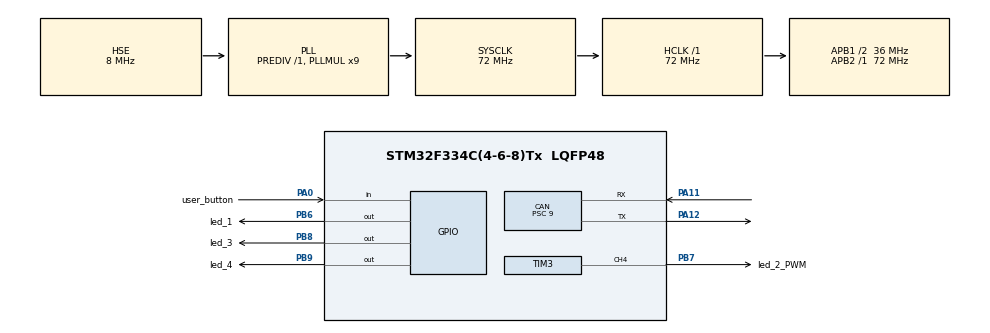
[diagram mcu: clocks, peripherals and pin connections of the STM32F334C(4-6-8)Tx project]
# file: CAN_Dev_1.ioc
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CAN.ABOM=ENABLE
CAN.BS1=CAN_BS1_13TQ
CAN.BS2=CAN_BS2_2TQ
CAN.CalculateBaudRate=250000
CAN.CalculateTimeBit=4000
CAN.CalculateTimeQuantum=250.0
CAN.NART=ENABLE
CAN.Prescaler=9
CAN.TXFP=ENABLE
Mcu.Family=STM32F3
Mcu.Name=STM32F334C(4-6-8)Tx
Mcu.Package=LQFP48
NVIC.CAN_RX0_IRQn=true\:11\:0\:true\:false\:true\:true\:true\:true
NVIC.CAN_TX_IRQn=true\:12\:0\:true\:false\:true\:true\:true\:true
NVIC.PriorityGroup=NVIC_PRIORITYGROUP_4
PA0.GPIO_Label=user_button
PA0.Signal=GPIO_Input
PA11.Mode=CAN_Activate
PA11.Signal=CAN_RX
PA12.Mode=CAN_Activate
PA12.Signal=CAN_TX
PA13.Mode=Serial_Wire
PA13.Signal=SYS_JTMS-SWDIO
PA14.Mode=Serial_Wire
PA14.Signal=SYS_JTCK-SWCLK
PB6.GPIO_Label=led_1
PB6.Signal=GPIO_Output
PB7.GPIO_Label=led_2_PWM
PB7.Signal=S_TIM3_CH4
PB8.GPIO_Label=led_3
PB8.Signal=GPIO_Output
PB9.GPIO_Label=led_4
PB9.Signal=GPIO_Output
PF0\ /\ OSC_IN.Mode=HSE-External-Oscillator
PF0\ /\ OSC_IN.Signal=RCC_OSC_IN
PF1\ /\ OSC_OUT.Mode=HSE-External-Oscillator
PF1\ /\ OSC_OUT.Signal=RCC_OSC_OUT
ProjectManager.HeapSize=0x200
ProjectManager.StackSize=0x400
ProjectManager.TargetToolchain=MDK-ARM V5.32
RCC.AHBFreq_Value=72000000
RCC.APB1CLKDivider=RCC_HCLK_DIV2
RCC.APB1Freq_Value=36000000
RCC.APB1TimFreq_Value=72000000
RCC.APB2Freq_Value=72000000
RCC.APB2TimFreq_Value=72000000
RCC.CortexFreq_Value=72000000
RCC.HCLKFreq_Value=72000000
RCC.HSI_VALUE=8000000
RCC.LSE_VALUE=32768
RCC.PLLMUL=RCC_PLL_MUL9
RCC.PLLSourceVirtual=RCC_PLLSOURCE_HSE
RCC.SYSCLKFreq_VALUE=72000000
RCC.SYSCLKSourceVirtual=RCC_SYSCLKSOURCE_PLLCLK
SH.S_TIM3_CH4.0=TIM3_CH4,PWM Generation4 CH4
TIM3.AutoReloadPreload=TIM_AUTORELOAD_PRELOAD_ENABLE
TIM3.Channel-PWM\ Generation4\ CH4=TIM_CHANNEL_4
TIM3.ClockDivision=TIM_CLOCKDIVISION_DIV4
TIM3.Pulse-PWM\ Generation4\ CH4=32000
board=custom

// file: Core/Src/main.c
/* USER CODE BEGIN Header */
/**
  ******************************************************************************
  * @file           : main.c
  * @brief          : Main program body
  ******************************************************************************
  * @attention
  *
  * Copyright (c) 2023 STMicroelectronics.
  * All rights reserved.
  *
  * This software is licensed under terms that can be found in the LICENSE file
  * in the root directory of this software component.
  * If no LICENSE file comes with this software, it is provided AS-IS.
  *
  ******************************************************************************
  */
/* USER CODE END Header */
#include "main.h"
#include "can.h"
#include "tim.h"
#include "gpio.h"

/* USER CODE BEGIN PV */
uint8_t pulse;
uint8_t pulse2;
uint8_t butSost;

CAN_TxHeaderTypeDef TxHeader;
CAN_RxHeaderTypeDef RxHeader;
uint8_t TxData[8] = {0,};
uint8_t RxData[8] = {0,};
uint32_t TxMailbox = 0;

/* USER CODE END PV */

void SystemClock_Config(void);
/* USER CODE BEGIN PFP */
void ledBlink(uint8_t timeBlink);
/* USER CODE END PFP */

/* USER CODE BEGIN 0 */
void HAL_CAN_RxFifo0MsgPendingCallback(CAN_HandleTypeDef *hcan)
{
    if(HAL_CAN_GetRxMessage(hcan, CAN_RX_FIFO0, &RxHeader, RxData) == HAL_OK)
    {
       pulse2 = RxData[7];
       HAL_GPIO_TogglePin(GPIOB, led_4_Pin);
    }
}
/* USER CODE END 0 */

int main(void)
{

  /* MCU Configuration--------------------------------------------------------*/

  /* Reset of all peripherals, Initializes the Flash interface and the Systick. */
  HAL_Init();

  /* Configure the system clock */
  SystemClock_Config();

  /* Initialize all configured peripherals */
  MX_GPIO_Init();
  MX_CAN_Init();
  MX_TIM3_Init();
  /* USER CODE BEGIN 2 */
  HAL_TIM_PWM_Start(&htim3, TIM_CHANNEL_4);
  /* USER CODE END 2 */
  TxData[7] = 10;

  TxHeader.StdId = 0x0378;
  TxHeader.ExtId = 0;
  TxHeader.RTR = CAN_RTR_DATA; //CAN_RTR_REMOTE
  TxHeader.IDE = CAN_ID_STD;   // CAN_ID_EXT
  TxHeader.DLC = 8;
  TxHeader.TransmitGlobalTime = 0;

  HAL_CAN_Start(&hcan);
  HAL_CAN_ActivateNotification(&hcan, CAN_IT_RX_FIFO0_MSG_PENDING | CAN_IT_ERROR | CAN_IT_BUSOFF | CAN_IT_LAST_ERROR_CODE);
  /* Infinite loop */
  while (1)
  {
    ledBlink(pulse2);

    butSost = HAL_GPIO_ReadPin(user_button_GPIO_Port, user_button_Pin);
    if(butSost) {
      while(butSost) {
        butSost = HAL_GPIO_ReadPin(user_button_GPIO_Port, user_button_Pin);
      }
      pulse += 1;
    }
    if(pulse >= 4) {
      pulse = 0;
    }

    TxData[7] = pulse;

    if(HAL_CAN_GetTxMailboxesFreeLevel(&hcan) != 0) {
      HAL_CAN_AddTxMessage(&hcan, &TxHeader, TxData, &TxMailbox);
    }

    HAL_Delay(200);

  }
}

void SystemClock_Config(void)
{
  RCC_OscInitTypeDef RCC_OscInitStruct = {0};
  RCC_ClkInitTypeDef RCC_ClkInitStruct = {0};

  /** Initializes the RCC Oscillators according to the specified parameters
  * in the RCC_OscInitTypeDef structure.
  */
  RCC_OscInitStruct.OscillatorType = RCC_OSCILLATORTYPE_HSE;
  RCC_OscInitStruct.HSEState = RCC_HSE_ON;
  RCC_OscInitStruct.HSEPredivValue = RCC_HSE_PREDIV_DIV1;
  RCC_OscInitStruct.HSIState = RCC_HSI_ON;
  RCC_OscInitStruct.PLL.PLLState = RCC_PLL_ON;
  RCC_OscInitStruct.PLL.PLLSource = RCC_PLLSOURCE_HSE;
  RCC_OscInitStruct.PLL.PLLMUL = RCC_PLL_MUL9;
  if (HAL_RCC_OscConfig(&RCC_OscInitStruct) != HAL_OK)
  {
    Error_Handler();
  }

  /** Initializes the CPU, AHB and APB buses clocks
  */
  RCC_ClkInitStruct.ClockType = RCC_CLOCKTYPE_HCLK|RCC_CLOCKTYPE_SYSCLK
                              |RCC_CLOCKTYPE_PCLK1|RCC_CLOCKTYPE_PCLK2;
  RCC_ClkInitStruct.SYSCLKSource = RCC_SYSCLKSOURCE_PLLCLK;
  RCC_ClkInitStruct.AHBCLKDivider = RCC_SYSCLK_DIV1;
  RCC_ClkInitStruct.APB1CLKDivider = RCC_HCLK_DIV2;
  RCC_ClkInitStruct.APB2CLKDivider = RCC_HCLK_DIV1;

  if (HAL_RCC_ClockConfig(&RCC_ClkInitStruct, FLASH_LATENCY_2) != HAL_OK)
  {
    Error_Handler();
  }
}

void Error_Handler(void)
{
  __disable_irq();
  while (1)
  {
  }
}

void ledBlink(uint8_t timeBlink) {

  switch (timeBlink) {
  	case 1:
      HAL_GPIO_WritePin(GPIOB, led_1_Pin, GPIO_PIN_SET);
  	  HAL_GPIO_WritePin(GPIOB, led_3_Pin, GPIO_PIN_RESET);
  		break;

  	case 2:
      HAL_GPIO_WritePin(GPIOB, led_3_Pin, GPIO_PIN_SET);
  	  HAL_GPIO_WritePin(GPIOB, led_1_Pin, GPIO_PIN_RESET);
  		break;

  	default:
  	  HAL_GPIO_WritePin(GPIOB, led_1_Pin|led_3_Pin, GPIO_PIN_RESET);
  		break;
  }

}
